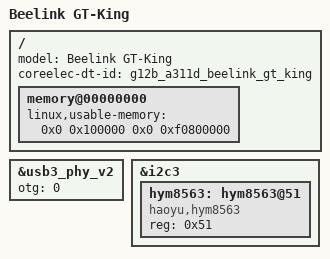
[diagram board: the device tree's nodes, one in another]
#include "g12b_a311d_coreelec.dts"

/{
	model = "Beelink GT-King";
	coreelec-dt-id = "g12b_a311d_beelink_gt_king";

	memory@00000000 {
		linux,usable-memory = <0x0 0x100000 0x0 0xf0800000>;
	};
};

&usb3_phy_v2 {
	otg = <0>;
};

&i2c3 {
	hym8563: hym8563@51 {
		compatible = "haoyu,hym8563";
		reg = <0x51>;
	};
};
